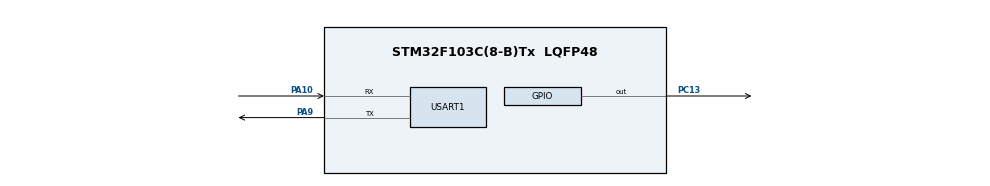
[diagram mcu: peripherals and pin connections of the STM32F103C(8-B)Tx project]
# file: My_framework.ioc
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Dma.Request0=USART1_RX
Dma.USART1_RX.0.Direction=DMA_PERIPH_TO_MEMORY
Dma.USART1_RX.0.Instance=DMA1_Channel5
Dma.USART1_RX.0.MemDataAlignment=DMA_MDATAALIGN_BYTE
Dma.USART1_RX.0.MemInc=DMA_MINC_ENABLE
Dma.USART1_RX.0.Mode=DMA_NORMAL
Dma.USART1_RX.0.PeriphDataAlignment=DMA_PDATAALIGN_BYTE
Dma.USART1_RX.0.PeriphInc=DMA_PINC_DISABLE
Dma.USART1_RX.0.Priority=DMA_PRIORITY_LOW
FREERTOS.Tasks01=defaultTask,24,128,StartDefaultTask,Default,NULL,Dynamic,NULL,NULL
Mcu.Family=STM32F1
Mcu.Name=STM32F103C(8-B)Tx
Mcu.Package=LQFP48
NVIC.DMA1_Channel5_IRQn=true\:5\:0\:false\:false\:true\:true\:false\:true\:true
NVIC.PriorityGroup=NVIC_PRIORITYGROUP_4
NVIC.USART1_IRQn=true\:5\:0\:false\:false\:true\:true\:true\:true\:true
PA10.Mode=Asynchronous
PA10.Signal=USART1_RX
PA13.Mode=Serial_Wire
PA13.Signal=SYS_JTMS-SWDIO
PA14.Mode=Serial_Wire
PA14.Signal=SYS_JTCK-SWCLK
PA9.Mode=Asynchronous
PA9.Signal=USART1_TX
PC13-TAMPER-RTC.Signal=GPIO_Output
PD0-OSC_IN.Mode=HSE-External-Oscillator
PD0-OSC_IN.Signal=RCC_OSC_IN
PD1-OSC_OUT.Mode=HSE-External-Oscillator
PD1-OSC_OUT.Signal=RCC_OSC_OUT
ProjectManager.HeapSize=0x200
ProjectManager.StackSize=0x400
ProjectManager.TargetToolchain=CMake
RCC.APB1Freq_Value=8000000
RCC.APB2Freq_Value=8000000
USART1.VirtualMode=VM_ASYNC
VP_FREERTOS_VS_CMSIS_V2.Mode=CMSIS_V2
board=custom

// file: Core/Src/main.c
/* USER CODE BEGIN Header */
/**
  ******************************************************************************
  * @file           : main.c
  * @brief          : Main program body
  ******************************************************************************
  * @attention
  *
  *
  *
  * Copyright (c) 2026 STMicroelectronics.
  * All rights reserved.
  *
  * This software is licensed under terms that can be found in the LICENSE file
  * in the root directory of this software component.
  * If no LICENSE file comes with this software, it is provided AS-IS.
  *
  ******************************************************************************
  */
 //extern void App_Init(void);
/* USER CODE END Header */
#include "main.h"
#include "cmsis_os.h"
#include "dma.h"
#include "usart.h"
#include "gpio.h"

/* USER CODE BEGIN Includes */
extern void App_Init(void);
extern void User_Uart_RX_Callback(uint8_t* data, uint16_t len);
/* USER CODE END Includes */

/* USER CODE BEGIN PV */
uint8_t g_rx_buffer[64];
/* USER CODE END PV */

void SystemClock_Config(void);
void MX_FREERTOS_Init(void);

int main(void)
{

  /* MCU Configuration--------------------------------------------------------*/

  /* Reset of all peripherals, Initializes the Flash interface and the Systick. */
  HAL_Init();

  /* Configure the system clock */
  SystemClock_Config();

  /* Initialize all configured peripherals */
  MX_GPIO_Init();
  MX_DMA_Init();
  MX_USART1_UART_Init();
  /* USER CODE BEGIN 2 */
 // static uint8_t g_rx_buffer[64];
  HAL_UART_Receive_DMA(&huart1, g_rx_buffer, sizeof(g_rx_buffer));

  App_Init();
  /* USER CODE END 2 */

  /* Init scheduler */
  osKernelInitialize();  /* Call init function for freertos objects (in cmsis_os2.c) */
  MX_FREERTOS_Init();

  /* Start scheduler */
  osKernelStart();

  /* We should never get here as control is now taken by the scheduler */

  /* Infinite loop */
  while (1)
  {

  }
}

void SystemClock_Config(void)
{
  RCC_OscInitTypeDef RCC_OscInitStruct = {0};
  RCC_ClkInitTypeDef RCC_ClkInitStruct = {0};

  /** Initializes the RCC Oscillators according to the specified parameters
  * in the RCC_OscInitTypeDef structure.
  */
  RCC_OscInitStruct.OscillatorType = RCC_OSCILLATORTYPE_HSI;
  RCC_OscInitStruct.HSIState = RCC_HSI_ON;
  RCC_OscInitStruct.HSICalibrationValue = RCC_HSICALIBRATION_DEFAULT;
  RCC_OscInitStruct.PLL.PLLState = RCC_PLL_NONE;
  if (HAL_RCC_OscConfig(&RCC_OscInitStruct) != HAL_OK)
  {
    Error_Handler();
  }

  /** Initializes the CPU, AHB and APB buses clocks
  */
  RCC_ClkInitStruct.ClockType = RCC_CLOCKTYPE_HCLK|RCC_CLOCKTYPE_SYSCLK
                              |RCC_CLOCKTYPE_PCLK1|RCC_CLOCKTYPE_PCLK2;
  RCC_ClkInitStruct.SYSCLKSource = RCC_SYSCLKSOURCE_HSI;
  RCC_ClkInitStruct.AHBCLKDivider = RCC_SYSCLK_DIV1;
  RCC_ClkInitStruct.APB1CLKDivider = RCC_HCLK_DIV1;
  RCC_ClkInitStruct.APB2CLKDivider = RCC_HCLK_DIV1;

  if (HAL_RCC_ClockConfig(&RCC_ClkInitStruct, FLASH_LATENCY_0) != HAL_OK)
  {
    Error_Handler();
  }
}

/* USER CODE BEGIN 4 */
extern uint8_t g_rx_buffer[64];

void HAL_UART_RxCpltCallback(UART_HandleTypeDef *huart) {
      if (huart->Instance == USART1) {
      //
      //HAL_UART_RxCpltCallback(UART_HandleTypeDef *huart) {
     // uint8_t temp_buffer[64]= {0};
       // User_Uart_RX_Callback(g_rx_buffer, sizeof(g_rx_buffer));
       HAL_GPIO_TogglePin(GPIOC, GPIO_PIN_13);
        HAL_UART_Receive_DMA(&huart1, g_rx_buffer, sizeof(g_rx_buffer));
        //
      //User_Uart_RX_Callback(temp_buffer, sizeof(temp_buffer));
    }
}
/* USER CODE END 4 */

void Error_Handler(void)
{
  __disable_irq();
  while (1)
  {
  }
}
